VERSION ""

NS_ :

BS_:

BU_:
VAL_TABLE_ work_mode 35 "manual mode" 18 "calibration mode" 17 "start up" ;
VAL_TABLE_ SteeringStateFbk 5 "Paddle Mode" 4 "Fail" 3 "Inspect" 2 "Purge" 1 "Calibration" 0 "Normal" ;
VAL_TABLE_ CalStatus 7 "N/A" 4 "Freeze" 3 "Reserved" 2 "Stbd Cal" 1 "Port Cal" 0 "Move" ;
VAL_TABLE_ SteeringStateRqst 12 "Center Cylinders" 5 "Fail" 4 "Inspect" 3 "Purge Stbd" 2 "Purge Port" 1 "Calibrate" 0 "Normal" ;

BO_ 3221225472 VECTOR__INDEPENDENT_SIG_MSG: 0 Vector__XXX
 SG_ Trim_Angle_combine : 0|40@0- (1E-009,240) [0|0] "" Vector__XXX
 SG_ TrimAngle_Rough : 0|8@1- (2.5,0) [0|0] "" Vector__XXX
 SG_ Trim_Angle : 0|16@0- (0.0002,0) [0|0] "" Vector__XXX
 SG_ B_6_7 : 0|16@1+ (1,0) [0|0] "" Vector__XXX
 SG_ B_3_4 : 0|16@1+ (1,0) [0|0] "" Vector__XXX
 SG_ B_5_6_7_big : 0|24@0+ (1,0) [0|0] "" Vector__XXX
 SG_ B_2_3_4_big : 0|24@0+ (1,0) [0|0] "" Vector__XXX
 SG_ B_5_6_big : 0|16@0+ (1,0) [0|0] "" Vector__XXX
 SG_ B_2_3_big : 0|16@0+ (1,0) [0|0] "" Vector__XXX
 SG_ B7 : 0|8@1+ (1,0) [0|0] "" Vector__XXX
 SG_ B6 : 0|8@1+ (1,0) [0|0] "" Vector__XXX
 SG_ B5 : 0|8@1+ (1,0) [0|0] "" Vector__XXX
 SG_ B4 : 0|8@1+ (1,0) [0|0] "" Vector__XXX
 SG_ B3 : 0|8@1+ (1,0) [0|0] "" Vector__XXX
 SG_ B2 : 0|8@1+ (1,0) [0|0] "" Vector__XXX
 SG_ B1 : 0|8@1+ (1,0) [0|0] "" Vector__XXX
 SG_ B0 : 0|8@1+ (1,0) [0|0] "" Vector__XXX
 SG_ B0 : 0|8@1+ (1,0) [0|0] "" Vector__XXX

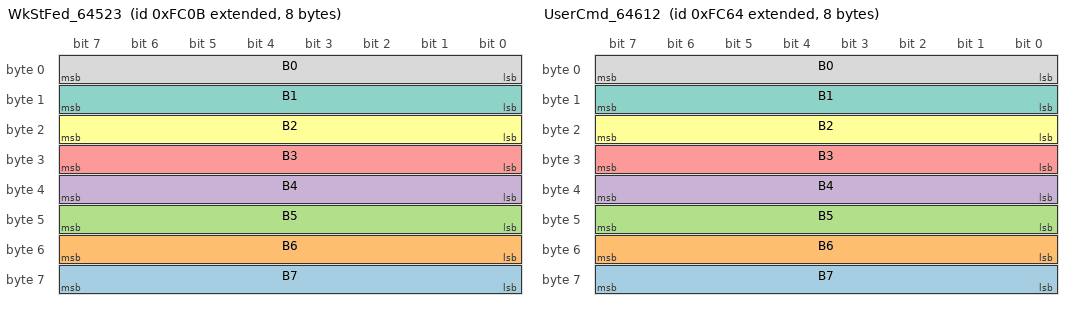
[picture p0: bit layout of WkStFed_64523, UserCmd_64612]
BO_ 2147548171 WkStFed_64523: 8 Vector__XXX
 SG_ B7 : 56|8@1+ (1,0) [0|0] "" Vector__XXX
 SG_ B6 : 48|8@1+ (1,0) [0|0] "" Vector__XXX
 SG_ B5 : 40|8@1+ (1,0) [0|0] "" Vector__XXX
 SG_ B4 : 32|8@1+ (1,0) [0|0] "" Vector__XXX
 SG_ B3 : 24|8@1+ (1,0) [0|0] "" Vector__XXX
 SG_ B2 : 16|8@1+ (1,0) [0|0] "" Vector__XXX
 SG_ B1 : 8|8@1+ (1,0) [0|0] "" Vector__XXX
 SG_ B0 : 0|8@1+ (1,0) [0|0] "" Vector__XXX

BO_ 2147548260 UserCmd_64612: 8 Vector__XXX
 SG_ B7 : 56|8@1+ (1,0) [0|0] "" Vector__XXX
 SG_ B6 : 48|8@1+ (1,0) [0|0] "" Vector__XXX
 SG_ B5 : 40|8@1+ (1,0) [0|0] "" Vector__XXX
 SG_ B4 : 32|8@1+ (1,0) [0|0] "" Vector__XXX
 SG_ B3 : 24|8@1+ (1,0) [0|0] "" Vector__XXX
 SG_ B2 : 16|8@1+ (1,0) [0|0] "" Vector__XXX
 SG_ B1 : 8|8@1+ (1,0) [0|0] "" Vector__XXX
 SG_ B0 : 0|8@1+ (1,0) [0|0] "" Vector__XXX

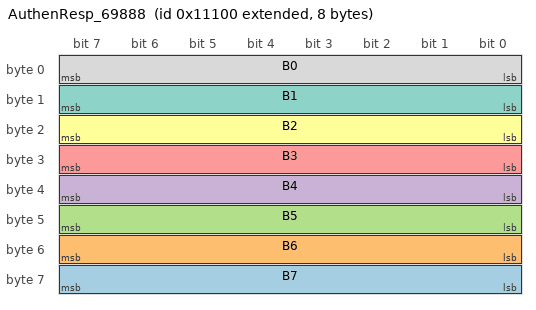
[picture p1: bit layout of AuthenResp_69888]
BO_ 2147553536 AuthenResp_69888: 8 Vector__XXX
 SG_ B7 : 56|8@1+ (1,0) [0|0] "" Vector__XXX
 SG_ B6 : 48|8@1+ (1,0) [0|0] "" Vector__XXX
 SG_ B5 : 40|8@1+ (1,0) [0|0] "" Vector__XXX
 SG_ B4 : 32|8@1+ (1,0) [0|0] "" Vector__XXX
 SG_ B3 : 24|8@1+ (1,0) [0|0] "" Vector__XXX
 SG_ B2 : 16|8@1+ (1,0) [0|0] "" Vector__XXX
 SG_ B1 : 8|8@1+ (1,0) [0|0] "" Vector__XXX
 SG_ B0 : 0|8@1+ (1,0) [0|0] "" Vector__XXX

BO_ 2147553280 CfgCmd_69632: 8 Vector__XXX

BO_ 2147548160 WkCmd_64512: 8 Vector__XXX
 SG_ work_mode : 0|8@1+ (1,0) [0|0] "" Vector__XXX
 SG_ Byte6_Bit4to7 : 52|4@1+ (1,0) [0|0] "" Vector__XXX
 SG_ Byte6_Bit0to3 : 48|4@1+ (1,0) [0|0] "" Vector__XXX
 SG_ Byte3_Bit4to7 : 28|4@1+ (1,0) [0|0] "" Vector__XXX
 SG_ Byte3_Bit0to3 : 24|4@1+ (1,0) [0|0] "" Vector__XXX
 SG_ B7 : 56|8@1+ (1,0) [0|0] "" Vector__XXX
 SG_ B6 : 48|8@1+ (1,0) [0|0] "" Vector__XXX
 SG_ B5 : 40|8@1+ (1,0) [0|0] "" Vector__XXX
 SG_ B4 : 32|8@1+ (1,0) [0|0] "" Vector__XXX
 SG_ B3 : 24|8@1+ (1,0) [0|0] "" Vector__XXX
 SG_ B2 : 16|8@1+ (1,0) [0|0] "" Vector__XXX
 SG_ B1 : 8|8@1+ (1,0) [0|0] "" Vector__XXX

BO_ 2147548215 Roll_Pitch_Ang_64567: 8 Vector__XXX
 SG_ RollAng_pot : 0|16@1+ (0.005,-160) [0|0] "deg" Vector__XXX
 SG_ PitchAng_pot : 16|16@1+ (0.005,-160) [0|0] "deg" Vector__XXX
 SG_ B7 : 56|8@1+ (1,0) [0|0] "" Vector__XXX
 SG_ B6 : 48|8@1+ (1,0) [0|0] "" Vector__XXX
 SG_ B5 : 40|8@1+ (1,0) [0|0] "" Vector__XXX
 SG_ B4 : 32|8@1+ (1,0) [0|0] "" Vector__XXX
 SG_ B3 : 24|8@1+ (1,0) [0|0] "" Vector__XXX
 SG_ B2 : 16|8@1+ (1,0) [0|0] "" Vector__XXX
 SG_ B1 : 8|8@1+ (1,0) [0|0] "" Vector__XXX
 SG_ B0 : 0|8@1+ (1,0) [0|0] "" Vector__XXX

BO_ 2147548210 Roll_Pitch_Ang_64562: 8 Vector__XXX
 SG_ RollAng_pot : 0|16@1+ (0.005,-160) [0|0] "deg" Vector__XXX
 SG_ PitchAng_pot : 16|16@1+ (0.005,-160) [0|0] "deg" Vector__XXX

BO_ 2147548170 WkFed_64522: 8 Vector__XXX
 SG_ B0_M : 4|4@1+ (1,0) [0|0] "" Vector__XXX
 SG_ B0_L : 0|4@1+ (1,0) [0|0] "" Vector__XXX
 SG_ B_2_3_big : 23|16@0+ (1,0) [0|0] "" Vector__XXX
 SG_ PosFed_pot : 4|12@1+ (0.212,-381.6) [0|0] "deg" Vector__XXX
 SG_ B7 : 56|8@1+ (1,0) [0|0] "" Vector__XXX
 SG_ B6 : 48|8@1+ (1,0) [0|0] "" Vector__XXX
 SG_ B5 : 40|8@1+ (1,0) [0|0] "" Vector__XXX
 SG_ B4 : 32|8@1+ (1,0) [0|0] "" Vector__XXX
 SG_ B3 : 24|8@1+ (1,0) [0|0] "" Vector__XXX
 SG_ B2 : 16|8@1+ (1,0) [0|0] "" Vector__XXX
 SG_ B1 : 8|8@1+ (1,0) [0|0] "" Vector__XXX
 SG_ B0 : 0|8@1+ (1,0) [0|0] "" Vector__XXX
 SG_ B_1_2 : 8|16@1+ (1,0) [0|0] "" Vector__XXX
 SG_ B_0_1_2 : 0|24@1+ (1,0) [0|0] "" Vector__XXX
 SG_ B_0_1 : 0|16@1+ (1,0) [0|0] "" Vector__XXX

CM_ BO_ 3221225472 "This is a message for not used signals, created by Vector CANdb++ DBC OLE DB Provider.";
BA_DEF_  "BusType" STRING ;
BA_DEF_  "IsNMEA" INT 0 1;
BA_DEF_DEF_  "BusType" "CAN";
BA_DEF_DEF_  "IsNMEA" 1;
VAL_ 2147548160 work_mode 35 "manual mode" 18 "calibration mode" 17 "start up" ;
